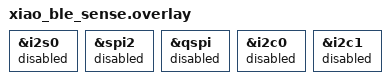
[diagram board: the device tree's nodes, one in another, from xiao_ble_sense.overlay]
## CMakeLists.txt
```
# SPDX-License-Identifier: Apache-2.0
set(BOARD xiao_ble/nrf52840/sense)
cmake_minimum_required(VERSION 3.20.0)
set(KCONFIG_ROOT ${CMAKE_CURRENT_SOURCE_DIR}/Kconfig)
find_package(Zephyr REQUIRED HINTS $ENV{ZEPHYR_BASE})
project(xiao_minimal)
enable_language(C ASM)

target_include_directories(app PRIVATE
  ${CMAKE_CURRENT_SOURCE_DIR}/../devkit/src
)

target_sources(app PRIVATE
  src/main.c
  src/transport.c
  src/stubs.c

  ../devkit/src/mic.c
  ../devkit/src/codec.c
  ../devkit/src/led.c
  ../devkit/src/button.c
  ../devkit/src/usb.c
  ../devkit/src/wdog_facade.c
  ../devkit/src/lib/battery/battery.c
)

target_sources_ifdef(CONFIG_OMI_CODEC_OPUS app PRIVATE
  ../devkit/src/lib/opus-1.2.1/A2NLSF.c
  ../devkit/src/lib/opus-1.2.1/CNG.c
  ../devkit/src/lib/opus-1.2.1/HP_variable_cutoff.c
  ../devkit/src/lib/opus-1.2.1/LPC_analysis_filter.c
  ../devkit/src/lib/opus-1.2.1/LPC_fit.c
  ../devkit/src/lib/opus-1.2.1/LPC_inv_pred_gain.c
  ../devkit/src/lib/opus-1.2.1/LP_variable_cutoff.c
  ../devkit/src/lib/opus-1.2.1/LTP_analysis_filter_FIX.c
  ../devkit/src/lib/opus-1.2.1/LTP_scale_ctrl_FIX.c
  ../devkit/src/lib/opus-1.2.1/NLSF2A.c
  ../devkit/src/lib/opus-1.2.1/NLSF_VQ.c
  ../devkit/src/lib/opus-1.2.1/NLSF_VQ_weights_laroia.c
  ../devkit/src/lib/opus-1.2.1/NLSF_decode.c
  ../devkit/src/lib/opus-1.2.1/NLSF_del_dec_quant.c
  ../devkit/src/lib/opus-1.2.1/NLSF_encode.c
  ../devkit/src/lib/opus-1.2.1/NLSF_stabilize.c
  ../devkit/src/lib/opus-1.2.1/NLSF_unpack.c
  ../devkit/src/lib/opus-1.2.1/NSQ.c
  ../devkit/src/lib/opus-1.2.1/NSQ_del_dec.c
  ../devkit/src/lib/opus-1.2.1/PLC.c
  ../devkit/src/lib/opus-1.2.1/VAD.c
  ../devkit/src/lib/opus-1.2.1/VQ_WMat_EC.c
  ../devkit/src/lib/opus-1.2.1/ana_filt_bank_1.c
  ../devkit/src/lib/opus-1.2.1/analysis.c
  ../devkit/src/lib/opus-1.2.1/apply_sine_window_FIX.c
  ../devkit/src/lib/opus-1.2.1/autocorr_FIX.c
  ../devkit/src/lib/opus-1.2.1/bands.c
  ../devkit/src/lib/opus-1.2.1/biquad_alt.c
  ../devkit/src/lib/opus-1.2.1/burg_modified_FIX.c
  ../devkit/src/lib/opus-1.2.1/bwexpander.c
  ../devkit/src/lib/opus-1.2.1/bwexpander_32.c
  ../devkit/src/lib/opus-1.2.1/celt.c
  ../devkit/src/lib/opus-1.2.1/celt_decoder.c
  ../devkit/src/lib/opus-1.2.1/celt_encoder.c
  ../devkit/src/lib/opus-1.2.1/celt_lpc.c
  ../devkit/src/lib/opus-1.2.1/arm/celt_pitch_xcorr_arm_gcc.s
  ../devkit/src/lib/opus-1.2.1/check_control_input.c
  ../devkit/src/lib/opus-1.2.1/code_signs.c
  ../devkit/src/lib/opus-1.2.1/control_SNR.c
  ../devkit/src/lib/opus-1.2.1/control_audio_bandwidth.c
  ../devkit/src/lib/opus-1.2.1/control_codec.c
  ../devkit/src/lib/opus-1.2.1/corrMatrix_FIX.c
  ../devkit/src/lib/opus-1.2.1/cwrs.c
  ../devkit/src/lib/opus-1.2.1/debug.c
  ../devkit/src/lib/opus-1.2.1/dec_API.c
  ../devkit/src/lib/opus-1.2.1/decode_core.c
  ../devkit/src/lib/opus-1.2.1/decode_frame.c
  ../devkit/src/lib/opus-1.2.1/decode_indices.c
  ../devkit/src/lib/opus-1.2.1/decode_parameters.c
  ../devkit/src/lib/opus-1.2.1/decode_pitch.c
  ../devkit/src/lib/opus-1.2.1/decode_pulses.c
  ../devkit/src/lib/opus-1.2.1/decoder_set_fs.c
  ../devkit/src/lib/opus-1.2.1/enc_API.c
  ../devkit/src/lib/opus-1.2.1/encode_frame_FIX.c
  ../devkit/src/lib/opus-1.2.1/encode_indices.c
  ../devkit/src/lib/opus-1.2.1/encode_pulses.c
  ../devkit/src/lib/opus-1.2.1/entcode.c
  ../devkit/src/lib/opus-1.2.1/entdec.c
  ../devkit/src/lib/opus-1.2.1/entenc.c
  ../devkit/src/lib/opus-1.2.1/find_LPC_FIX.c
  ../devkit/src/lib/opus-1.2.1/find_LTP_FIX.c
  ../devkit/src/lib/opus-1.2.1/find_pitch_lags_FIX.c
  ../devkit/src/lib/opus-1.2.1/find_pred_coefs_FIX.c
  ../devkit/src/lib/opus-1.2.1/gain_quant.c
  ../devkit/src/lib/opus-1.2.1/init_decoder.c
  ../devkit/src/lib/opus-1.2.1/init_encoder.c
  ../devkit/src/lib/opus-1.2.1/inner_prod_aligned.c
  ../devkit/src/lib/opus-1.2.1/interpolate.c
  ../devkit/src/lib/opus-1.2.1/k2a_FIX.c
  ../devkit/src/lib/opus-1.2.1/k2a_Q16_FIX.c
  ../devkit/src/lib/opus-1.2.1/kiss_fft.c
  ../devkit/src/lib/opus-1.2.1/laplace.c
  ../devkit/src/lib/opus-1.2.1/lin2log.c
  ../devkit/src/lib/opus-1.2.1/log2lin.c
  ../devkit/src/lib/opus-1.2.1/mathops.c
  ../devkit/src/lib/opus-1.2.1/mdct.c
  ../devkit/src/lib/opus-1.2.1/mlp.c
  ../devkit/src/lib/opus-1.2.1/mlp_data.c
  ../devkit/src/lib/opus-1.2.1/modes.c
  ../devkit/src/lib/opus-1.2.1/noise_shape_analysis_FIX.c
  ../devkit/src/lib/opus-1.2.1/opus.c
  ../devkit/src/lib/opus-1.2.1/opus_decoder.c
  ../devkit/src/lib/opus-1.2.1/opus_encoder.c
  ../devkit/src/lib/opus-1.2.1/opus_multistream.c
  ../devkit/src/lib/opus-1.2.1/opus_multistream_decoder.c
  ../devkit/src/lib/opus-1.2.1/opus_multistream_encoder.c
  ../devkit/src/lib/opus-1.2.1/pitch.c
  ../devkit/src/lib/opus-1.2.1/pitch_analysis_core_FIX.c
  ../devkit/src/lib/opus-1.2.1/pitch_est_tables.c
  ../devkit/src/lib/opus-1.2.1/process_NLSFs.c
  ../devkit/src/lib/opus-1.2.1/process_gains_FIX.c
  ../devkit/src/lib/opus-1.2.1/quant_LTP_gains.c
  ../devkit/src/lib/opus-1.2.1/quant_bands.c
  ../devkit/src/lib/opus-1.2.1/rate.c
  ../devkit/src/lib/opus-1.2.1/regularize_correlations_FIX.c
  ../devkit/src/lib/opus-1.2.1/repacketizer.c
  ../devkit/src/lib/opus-1.2.1/resampler.c
  ../devkit/src/lib/opus-1.2.1/resampler_down2.c
  ../devkit/src/lib/opus-1.2.1/resampler_down2_3.c
  ../devkit/src/lib/opus-1.2.1/resampler_private_AR2.c
  ../devkit/src/lib/opus-1.2.1/resampler_private_IIR_FIR.c
  ../devkit/src/lib/opus-1.2.1/resampler_private_down_FIR.c
  ../devkit/src/lib/opus-1.2.1/resampler_private_up2_HQ.c
  ../devkit/src/lib/opus-1.2.1/resampler_rom.c
  ../devkit/src/lib/opus-1.2.1/residual_energy16_FIX.c
  ../devkit/src/lib/opus-1.2.1/residual_energy_FIX.c
  ../devkit/src/lib/opus-1.2.1/schur64_FIX.c
  ../devkit/src/lib/opus-1.2.1/schur_FIX.c
  ../devkit/src/lib/opus-1.2.1/shell_coder.c
  ../devkit/src/lib/opus-1.2.1/sigm_Q15.c
  ../devkit/src/lib/opus-1.2.1/sort.c
  ../devkit/src/lib/opus-1.2.1/stereo_LR_to_MS.c
  ../devkit/src/lib/opus-1.2.1/stereo_MS_to_LR.c
  ../devkit/src/lib/opus-1.2.1/stereo_decode_pred.c
  ../devkit/src/lib/opus-1.2.1/stereo_encode_pred.c
  ../devkit/src/lib/opus-1.2.1/stereo_find_predictor.c
  ../devkit/src/lib/opus-1.2.1/stereo_quant_pred.c
  ../devkit/src/lib/opus-1.2.1/sum_sqr_shift.c
  ../devkit/src/lib/opus-1.2.1/table_LSF_cos.c
  ../devkit/src/lib/opus-1.2.1/tables_LTP.c
  ../devkit/src/lib/opus-1.2.1/tables_NLSF_CB_NB_MB.c
  ../devkit/src/lib/opus-1.2.1/tables_NLSF_CB_WB.c
  ../devkit/src/lib/opus-1.2.1/tables_gain.c
  ../devkit/src/lib/opus-1.2.1/tables_other.c
  ../devkit/src/lib/opus-1.2.1/tables_pitch_lag.c
  ../devkit/src/lib/opus-1.2.1/tables_pulses_per_block.c
  ../devkit/src/lib/opus-1.2.1/vector_ops_FIX.c
  ../devkit/src/lib/opus-1.2.1/vq.c
  ../devkit/src/lib/opus-1.2.1/warped_autocorrelation_FIX.c
)

set(CMAKE_C_FLAGS "${CMAKE_C_FLAGS} -DARM_MATH_CM4")
set(CMAKE_C_FLAGS "${CMAKE_C_FLAGS} -DOPUS_ARM_ASM")
set(CMAKE_C_FLAGS "${CMAKE_C_FLAGS} -DOPUS_ARM_INLINE_ASM")
set(CMAKE_C_FLAGS "${CMAKE_C_FLAGS} -DOPUS_ARM_INLINE_EDSP")
set(CMAKE_C_FLAGS "${CMAKE_C_FLAGS} -DOPUS_ARM_INLINE_MEDIA")
set(CMAKE_C_FLAGS "${CMAKE_C_FLAGS} -DOPUS_ARM_MAY_HAVE_EDSP")
set(CMAKE_C_FLAGS "${CMAKE_C_FLAGS} -DOPUS_ARM_PRESUME_EDSP")
set(CMAKE_C_FLAGS "${CMAKE_C_FLAGS} -DOPUS_BUILD")
set(CMAKE_C_FLAGS "${CMAKE_C_FLAGS} -DUSE_ALLOCA")
set(CMAKE_C_FLAGS "${CMAKE_C_FLAGS} -DFIXED_POINT -DDISABLE_FLOAT_API")
set(CMAKE_C_FLAGS "${CMAKE_C_FLAGS} -DHAVE_CONFIG_H")
set(CMAKE_C_FLAGS "${CMAKE_C_FLAGS} -DHAVE_ALLOCA_H")
set(CMAKE_C_FLAGS "${CMAKE_C_FLAGS} -fsingle-precision-constant")
set(CMAKE_C_FLAGS "${CMAKE_C_FLAGS} -DHAVE_LRINT -DHAVE_LRINTF")
```

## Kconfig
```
source "Kconfig.zephyr"

menu "Attune XIAO minimal options"

config OMI_CODEC_OPUS
    bool "Enable Opus codec"
    default y

config OMI_ENABLE_OFFLINE_STORAGE
    bool "Enable offline storage"
    select DISK_ACCESS
    select FILE_SYSTEM
    select FAT_FILESYSTEM_ELM
    select FS_FATFS_MOUNT_MKFS
    help
        Enable offline SD-card storage support.
    default n

config OMI_ENABLE_ACCELEROMETER
    bool "Enable accelerometer"
    help
        Enable accelerometer support.
    default n

config OMI_ENABLE_BUTTON
    bool "Enable button support"
    help
        Enable button handling.
    default y

config OMI_ENABLE_SPEAKER
    bool "Enable speaker support"
    help
        Enable speaker output support.
    default n

config OMI_ENABLE_BATTERY
    bool "Enable battery support"
    help
        Enable battery telemetry support.
    default y

if OMI_ENABLE_BATTERY

config OMI_BATTERY_GPIO_CHARGE_SPEED_PIN
    int "Battery charge-speed GPIO pin"
    default 13
    help
        GPIO pin index used for charger current selection.

config OMI_BATTERY_GPIO_CHARGING_ENABLE_PIN
    int "Battery charging-enable GPIO pin"
    default -1
    help
        GPIO pin index used to enable the charger path.
        Set to -1 when the board charger is autonomous (no enable pin).

config OMI_BATTERY_GPIO_CHARGE_STATUS_PIN
    int "Battery charge-status GPIO pin"
    default 17
    help
        GPIO pin index for charge status output from PMIC.
        Set to -1 when charge status is unavailable.

config OMI_BATTERY_GPIO_READ_ENABLE_PIN
    int "Battery read-enable GPIO pin"
    default 14
    help
        GPIO pin index used to enable battery voltage read circuitry.

config OMI_BATTERY_CHARGE_SPEED_ACTIVE_LOW
    bool "Charge-speed pin is active low"
    default y

config OMI_BATTERY_CHARGING_ENABLE_ACTIVE_LOW
    bool "Charging-enable pin is active low"
    default y

config OMI_BATTERY_CHARGE_STATUS_ACTIVE_LOW
    bool "Charge-status pin is active low"
    default y

config OMI_BATTERY_READ_ENABLE_ACTIVE_LOW
    bool "Read-enable pin is active low"
    default y

config OMI_BATTERY_ADC_R1_KOHM
    int "Battery divider R1 value (kOhm)"
    default 1000
    help
        Top resistor value for battery divider calibration.

config OMI_BATTERY_ADC_R2_KOHM
    int "Battery divider R2 value (kOhm)"
    default 510
    help
        Bottom resistor value for battery divider calibration.

endif

config OMI_ENABLE_USB
    bool "Enable USB support"
    help
        Enable USB power-check support.
    default y

config OMI_ENABLE_HAPTIC
    bool "Enable haptic support"
    help
        Enable haptic feedback support.
    default n

endmenu
```

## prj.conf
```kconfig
# Bare XIAO nRF52840 Sense minimal firmware

# Core HW
CONFIG_GPIO=y
CONFIG_ADC=y
CONFIG_NRFX_PDM=y
CONFIG_FLASH=y
CONFIG_WATCHDOG=y
CONFIG_WDT_DISABLE_AT_BOOT=n

# BLE
CONFIG_BT=y
CONFIG_BT_PERIPHERAL=y
CONFIG_BT_DEVICE_NAME="Attune XIAO Minimal"
CONFIG_BT_MAX_CONN=1
CONFIG_BT_MAX_PAIRED=1
CONFIG_BT_DEVICE_APPEARANCE=22
CONFIG_BT_GATT_DYNAMIC_DB=y
CONFIG_BT_BAS=y
CONFIG_BT_DIS=y
CONFIG_BT_DIS_PNP=n
CONFIG_BT_DIS_MODEL="Attune XIAO Minimal"
CONFIG_BT_DIS_MANUF="Based Hardware"
CONFIG_BT_DIS_FW_REV=y
CONFIG_BT_DIS_HW_REV=y
CONFIG_BT_DIS_FW_REV_STR="0.1.0"
CONFIG_BT_DIS_HW_REV_STR="Seeed XIAO nRF52840 Sense"

CONFIG_BT_CTLR_TX_PWR_ANTENNA=8
CONFIG_BT_PHY_UPDATE=y
CONFIG_BT_L2CAP_TX_MTU=498
CONFIG_BT_CTLR_DATA_LENGTH_MAX=251
CONFIG_BT_CTLR_PHY_2M=y
CONFIG_BT_CONN_TX_MAX=20
CONFIG_BT_BUF_ACL_RX_SIZE=1024
CONFIG_BT_L2CAP_TX_BUF_COUNT=10
CONFIG_BT_BUF_ACL_TX_SIZE=2048
CONFIG_BT_USER_DATA_LEN_UPDATE=y
CONFIG_BT_AUTO_DATA_LEN_UPDATE=y
CONFIG_BT_USER_PHY_UPDATE=y
CONFIG_BT_AUTO_PHY_UPDATE=y

# Logging / console for bring-up
CONFIG_CONSOLE=y
CONFIG_PRINTK=y
CONFIG_LOG=y
CONFIG_LOG_PRINTK=y
CONFIG_SERIAL=y
CONFIG_UART_CONSOLE=y
CONFIG_LOG_DEFAULT_LEVEL=3

# Omi feature toggles
CONFIG_OMI_CODEC_OPUS=y
CONFIG_OMI_ENABLE_OFFLINE_STORAGE=n
CONFIG_OMI_ENABLE_ACCELEROMETER=n
CONFIG_OMI_ENABLE_BUTTON=y
CONFIG_OMI_ENABLE_SPEAKER=n
CONFIG_OMI_ENABLE_BATTERY=y
CONFIG_OMI_ENABLE_USB=y
CONFIG_OMI_ENABLE_HAPTIC=n
CONFIG_OMI_BATTERY_GPIO_CHARGE_SPEED_PIN=-1
CONFIG_OMI_BATTERY_GPIO_CHARGING_ENABLE_PIN=-1
CONFIG_OMI_BATTERY_GPIO_CHARGE_STATUS_PIN=-1
CONFIG_OMI_BATTERY_GPIO_READ_ENABLE_PIN=-1
CONFIG_OMI_BATTERY_CHARGE_SPEED_ACTIVE_LOW=y
CONFIG_OMI_BATTERY_READ_ENABLE_ACTIVE_LOW=y
CONFIG_OMI_BATTERY_CHARGE_STATUS_ACTIVE_LOW=y
CONFIG_OMI_BATTERY_ADC_R1_KOHM=1000
CONFIG_OMI_BATTERY_ADC_R2_KOHM=510

CONFIG_RING_BUFFER=y
CONFIG_HEAP_MEM_POOL_SIZE=512
CONFIG_MAIN_STACK_SIZE=3072
```

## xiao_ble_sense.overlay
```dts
/* Bare XIAO Sense minimal overlay: explicitly disable peripherals not present */

&i2s0 {
    status = "disabled";
};

&spi2 {
    status = "disabled";
};

&qspi {
    status = "disabled";
};

&i2c0 {
    status = "disabled";
};

&i2c1 {
    status = "disabled";
};
```

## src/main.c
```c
#include <errno.h>
#include <zephyr/kernel.h>
#include <zephyr/logging/log.h>
#include <hal/nrf_power.h>

#include "button.h"
#include "codec.h"
#include "config.h"
#include "led.h"
#include "lib/battery/battery.h"
#include "mic.h"
#include "transport.h"
#include "usb.h"
#include "wdog_facade.h"

LOG_MODULE_REGISTER(main, CONFIG_LOG_DEFAULT_LEVEL);

bool is_connected = false;
bool is_charging = false;
extern bool is_off;
extern bool usb_charge;
static bool charger_state_initialized = false;
static bool charger_enabled = false;
static int64_t last_codec_error_log_ms = 0;
static int64_t last_battery_diag_log_ms = 0;

static void codec_handler(uint8_t *data, size_t len)
{
    if (!is_connected) {
        return;
    }

    int err = broadcast_audio_packets(data, len);
    if (err) {
        const int64_t now_ms = k_uptime_get();
        if ((now_ms - last_codec_error_log_ms) >= 1000) {
            last_codec_error_log_ms = now_ms;
            LOG_WRN("Audio packet broadcast backpressure (err=%d)", err);
        }
    }
}

static void mic_handler(int16_t *buffer)
{
    if (!is_connected) {
        return;
    }

    int err = codec_receive_pcm(buffer, MIC_BUFFER_SAMPLES);
    if (err) {
        const int64_t now_ms = k_uptime_get();
        if ((now_ms - last_codec_error_log_ms) >= 1000) {
            last_codec_error_log_ms = now_ms;
            LOG_WRN("PCM ingest backpressure (err=%d)", err);
        }
    }
}

void set_led_state(void)
{
    if (usb_charge) {
        is_charging = !is_charging;
        set_led_green(is_charging);
    } else {
        set_led_green(false);
    }

    if (is_off) {
        set_led_red(false);
        set_led_blue(false);
        return;
    }

    if (is_connected) {
        set_led_blue(true);
        set_led_red(false);
    } else {
        set_led_blue(false);
        set_led_red(true);
    }
}

static void apply_charger_policy(void)
{
#ifdef CONFIG_OMI_ENABLE_BATTERY
#if defined(CONFIG_OMI_BATTERY_GPIO_CHARGING_ENABLE_PIN) && (CONFIG_OMI_BATTERY_GPIO_CHARGING_ENABLE_PIN < 0)
    // XIAO build: charger enable is not firmware-controlled.
    return;
#else
    const bool should_charge = usb_charge;
    if (charger_state_initialized && charger_enabled == should_charge) {
        return;
    }

    const int err = should_charge ? battery_charge_start() : battery_charge_stop();
    if (err) {
        LOG_WRN("Battery charge policy update failed (usb=%d, err=%d)", should_charge, err);
        return;
    }

    charger_state_initialized = true;
    charger_enabled = should_charge;
    LOG_INF("Battery charger %s (usb=%d)", should_charge ? "enabled" : "disabled", usb_charge);
#endif
#endif
}

static void log_battery_diagnostics(void)
{
#ifdef CONFIG_OMI_ENABLE_BATTERY
    const int64_t now_ms = k_uptime_get();
    if ((now_ms - last_battery_diag_log_ms) < 10000) {
        return;
    }
    last_battery_diag_log_ms = now_ms;

    uint16_t battery_millivolt = 0;
    uint8_t battery_percent = 0xFF;
    bool charging = false;
    const int mv_err = battery_get_millivolt(&battery_millivolt);
    const int pct_err = (mv_err == 0)
        ? battery_get_percentage(&battery_percent, battery_millivolt)
        : -ENOTSUP;
    const int charge_err = battery_is_charge_enabled(&charging);

    LOG_INF("Battery main diag: mv=%u pct=%u usb=%d charging=%d errs[mv=%d pct=%d chg=%d]",
            battery_millivolt,
            battery_percent,
            usb_charge ? 1 : 0,
            charging ? 1 : 0,
            mv_err,
            pct_err,
            charge_err);
#endif
}

int main(void)
{
    int err;

    LOG_INF("Booting minimal XIAO firmware");
    LOG_INF("Model: %s", CONFIG_BT_DIS_MODEL);
    LOG_INF("FW: %s", CONFIG_BT_DIS_FW_REV_STR);
    const uint32_t reset_reason = NRF_POWER->RESETREAS;
    NRF_POWER->RESETREAS = reset_reason;
    LOG_INF("Reset reason: 0x%08x", reset_reason);

    err = led_start();
    if (err) {
        LOG_ERR("LED init failed: %d", err);
        return err;
    }

    err = watchdog_init();
    if (err) {
        LOG_WRN("Watchdog init failed: %d", err);
    }

#ifdef CONFIG_OMI_ENABLE_BATTERY
    err = battery_init();
    if (err) {
        LOG_ERR("Battery init failed: %d", err);
        return err;
    }
#endif

#ifdef CONFIG_OMI_ENABLE_BUTTON
    err = button_init();
    if (err) {
        LOG_ERR("Button init failed: %d", err);
        return err;
    }
    activate_button_work();
#endif

#ifdef CONFIG_OMI_ENABLE_USB
    err = init_usb();
    if (err) {
        LOG_ERR("USB init failed: %d", err);
        return err;
    }
#endif

#ifdef CONFIG_OMI_ENABLE_BATTERY
    apply_charger_policy();
#endif

    err = transport_start();
    if (err) {
        LOG_ERR("Transport start failed: %d", err);
        return err;
    }

    set_codec_callback(codec_handler);
    err = codec_start();
    if (err) {
        LOG_ERR("Codec start failed: %d", err);
        return err;
    }

    set_mic_callback(mic_handler);
    err = mic_start();
    if (err) {
        LOG_ERR("Mic start failed: %d", err);
        return err;
    }
    // Keep capture path off until BLE client connects or explicitly resumes.
    mic_off();

    LOG_INF("Minimal firmware initialized");

    while (1) {
        watchdog_feed();
        apply_charger_policy();
        log_battery_diagnostics();
        set_led_state();
        k_msleep(500);
    }

    return 0;
}
```

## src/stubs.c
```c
#include <stdbool.h>
#include <stdint.h>
#include <zephyr/kernel.h>

#include "speaker.h"

int speaker_init(void) { return 0; }
uint16_t speak(uint16_t len, const void *buf)
{
    ARG_UNUSED(buf);
    return len;
}
int play_boot_sound(void) { return 0; }
int init_haptic_pin(void) { return 0; }
void play_haptic_milli(uint32_t duration) { ARG_UNUSED(duration); }
void speaker_off(void) {}
void register_speaker_service(void) {}

int mount_sd_card(void) { return 0; }
void sd_on(void) {}
void sd_off(void) {}
bool is_sd_on(void) { return false; }
int write_to_file(uint8_t *buf, uint32_t len)
{
    ARG_UNUSED(buf);
    ARG_UNUSED(len);
    return 0;
}
uint32_t get_file_size(uint8_t file_num)
{
    ARG_UNUSED(file_num);
    return 0;
}
int get_offset(void) { return 0; }

int storage_init(void) { return 0; }

bool storage_is_on = false;
uint8_t file_count = 0;
uint32_t file_num_array[2] = {0};
```

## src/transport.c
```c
#include "transport.h"

#include <errno.h>
#include <zephyr/bluetooth/bluetooth.h>
#include <zephyr/bluetooth/gatt.h>
#include <zephyr/bluetooth/services/bas.h>
#include <zephyr/kernel.h>
#include <zephyr/logging/log.h>
#include <zephyr/sys/ring_buffer.h>
#include <zephyr/sys/util.h>

#include "button.h"
#include "codec.h"
#include "config.h"
#include "lib/battery/battery.h"
#include "mic.h"
#include "usb.h"
#include "utils.h"

LOG_MODULE_REGISTER(transport, CONFIG_LOG_DEFAULT_LEVEL);

extern bool is_connected;
extern bool is_off;
extern bool usb_charge;

struct bt_conn *current_connection = NULL;
uint16_t current_mtu = 0;
static struct ring_buf ring_buf;
static volatile bool stream_paused = true;
static volatile bool stream_notify_enabled = false;

static void audio_ccc_config_changed_handler(const struct bt_gatt_attr *attr, uint16_t value)
{
    ARG_UNUSED(attr);
    stream_notify_enabled = (value == BT_GATT_CCC_NOTIFY);
    if (!stream_notify_enabled) {
        ring_buf_reset(&ring_buf);
        mic_off();
    } else if (!stream_paused && is_connected) {
        mic_on();
    }
}

static ssize_t audio_data_read_characteristic(struct bt_conn *conn,
                                              const struct bt_gatt_attr *attr,
                                              void *buf,
                                              uint16_t len,
                                              uint16_t offset)
{
    return bt_gatt_attr_read(conn, attr, buf, len, offset, NULL, 0);
}

static ssize_t audio_codec_read_characteristic(struct bt_conn *conn,
                                               const struct bt_gatt_attr *attr,
                                               void *buf,
                                               uint16_t len,
                                               uint16_t offset)
{
    uint8_t value[1] = {CODEC_ID};
    return bt_gatt_attr_read(conn, attr, buf, len, offset, value, sizeof(value));
}

static ssize_t audio_mic_gain_read_characteristic(struct bt_conn *conn,
                                                  const struct bt_gatt_attr *attr,
                                                  void *buf,
                                                  uint16_t len,
                                                  uint16_t offset)
{
    ARG_UNUSED(attr);
    const uint8_t level = mic_get_gain_level();
    return bt_gatt_attr_read(conn, attr, buf, len, offset, &level, sizeof(level));
}

static ssize_t audio_mic_gain_write_characteristic(struct bt_conn *conn,
                                                   const struct bt_gatt_attr *attr,
                                                   const void *buf,
                                                   uint16_t len,
                                                   uint16_t offset,
                                                   uint8_t flags)
{
    ARG_UNUSED(conn);
    ARG_UNUSED(attr);
    ARG_UNUSED(offset);
    ARG_UNUSED(flags);

    if (buf == NULL || len < 1) {
        return 0;
    }

    const uint8_t requested = ((const uint8_t *)buf)[0];
    mic_set_gain_level(requested);
    return len;
}

enum {
    AUDIO_CTRL_CMD_PAUSE_STREAM = 0x01,
    AUDIO_CTRL_CMD_RESUME_STREAM = 0x02,
    AUDIO_CTRL_CMD_ENTER_DEEP_SLEEP = 0x03,
    AUDIO_CTRL_CMD_NOTIFY_STATUS = 0x04,
};

enum {
    AUDIO_STATUS_FLAG_USB_POWER = 1 << 0,
    AUDIO_STATUS_FLAG_CHARGING_ENABLED = 1 << 1,
    AUDIO_STATUS_FLAG_STREAM_PAUSED = 1 << 2,
};

static bool battery_filter_initialized = false;
static uint16_t battery_filtered_mv = 0;
static uint8_t battery_filtered_percent = 0xFF;
static int64_t battery_last_update_ms = 0;
static int64_t battery_diag_last_log_ms = 0;

static uint8_t stabilize_battery_percent(uint8_t raw_percent, uint16_t raw_mv)
{
    if (raw_percent == 0xFF) {
        return battery_filter_initialized ? battery_filtered_percent : raw_percent;
    }

    const int64_t now_ms = k_uptime_get();
    if (!battery_filter_initialized) {
        battery_filter_initialized = true;
        battery_filtered_mv = raw_mv;
        battery_filtered_percent = raw_percent;
        battery_last_update_ms = now_ms;
        return battery_filtered_percent;
    }

    if (raw_mv > 0) {
        // Exponential moving average to reduce load-induced voltage swings.
        battery_filtered_mv = (uint16_t)(((uint32_t)battery_filtered_mv * 7U + raw_mv) / 8U);
    }

    uint8_t candidate = raw_percent;
    if (battery_filtered_mv > 0) {
        (void)battery_get_percentage(&candidate, battery_filtered_mv);
    }

    int elapsed_s = (int)((now_ms - battery_last_update_ms) / 1000);
    if (elapsed_s < 1) {
        elapsed_s = 1;
    }

    const int prev = (int)battery_filtered_percent;
    const int max_rise = MIN(24, 2 + elapsed_s);
    const int max_fall = MIN(28, 3 + (elapsed_s * 2));
    int delta = (int)candidate - prev;
    if (delta > max_rise) {
        candidate = (uint8_t)(prev + max_rise);
    } else if (-delta > max_fall) {
        candidate = (uint8_t)(prev - max_fall);
    }

    battery_filtered_percent = candidate;
    battery_last_update_ms = now_ms;
    return battery_filtered_percent;
}

static ssize_t audio_control_write_characteristic(struct bt_conn *conn,
                                                  const struct bt_gatt_attr *attr,
                                                  const void *buf,
                                                  uint16_t len,
                                                  uint16_t offset,
                                                  uint8_t flags);
static ssize_t audio_status_read_characteristic(struct bt_conn *conn,
                                                const struct bt_gatt_attr *attr,
                                                void *buf,
                                                uint16_t len,
                                                uint16_t offset);
static void audio_status_ccc_config_changed_handler(const struct bt_gatt_attr *attr, uint16_t value);
static void audio_notify_status(struct bt_conn *conn);
static void audio_build_status_payload(uint8_t payload[5]);

static struct bt_uuid_128 audio_service_uuid =
    BT_UUID_INIT_128(BT_UUID_128_ENCODE(0x19B10000, 0xE8F2, 0x537E, 0x4F6C, 0xD104768A1214));
static struct bt_uuid_128 audio_characteristic_data_uuid =
    BT_UUID_INIT_128(BT_UUID_128_ENCODE(0x19B10001, 0xE8F2, 0x537E, 0x4F6C, 0xD104768A1214));
static struct bt_uuid_128 audio_characteristic_format_uuid =
    BT_UUID_INIT_128(BT_UUID_128_ENCODE(0x19B10002, 0xE8F2, 0x537E, 0x4F6C, 0xD104768A1214));
static struct bt_uuid_128 audio_characteristic_mic_gain_uuid =
    BT_UUID_INIT_128(BT_UUID_128_ENCODE(0x19B10003, 0xE8F2, 0x537E, 0x4F6C, 0xD104768A1214));
static struct bt_uuid_128 audio_characteristic_control_uuid =
    BT_UUID_INIT_128(BT_UUID_128_ENCODE(0x19B10004, 0xE8F2, 0x537E, 0x4F6C, 0xD104768A1214));
static struct bt_uuid_128 audio_characteristic_status_uuid =
    BT_UUID_INIT_128(BT_UUID_128_ENCODE(0x19B10005, 0xE8F2, 0x537E, 0x4F6C, 0xD104768A1214));

static struct bt_gatt_attr audio_service_attr[] = {
    BT_GATT_PRIMARY_SERVICE(&audio_service_uuid),
    BT_GATT_CHARACTERISTIC(&audio_characteristic_data_uuid.uuid,
                           BT_GATT_CHRC_READ | BT_GATT_CHRC_NOTIFY,
                           BT_GATT_PERM_READ,
                           audio_data_read_characteristic,
                           NULL,
                           NULL),
    BT_GATT_CCC(audio_ccc_config_changed_handler, BT_GATT_PERM_READ | BT_GATT_PERM_WRITE),
    BT_GATT_CHARACTERISTIC(&audio_characteristic_format_uuid.uuid,
                           BT_GATT_CHRC_READ,
                           BT_GATT_PERM_READ,
                           audio_codec_read_characteristic,
                           NULL,
                           NULL),
    BT_GATT_CHARACTERISTIC(&audio_characteristic_mic_gain_uuid.uuid,
                           BT_GATT_CHRC_READ | BT_GATT_CHRC_WRITE | BT_GATT_CHRC_WRITE_WITHOUT_RESP,
                           BT_GATT_PERM_READ | BT_GATT_PERM_WRITE,
                           audio_mic_gain_read_characteristic,
                           audio_mic_gain_write_characteristic,
                           NULL),
    BT_GATT_CHARACTERISTIC(&audio_characteristic_control_uuid.uuid,
                           BT_GATT_CHRC_WRITE | BT_GATT_CHRC_WRITE_WITHOUT_RESP,
                           BT_GATT_PERM_WRITE,
                           NULL,
                           audio_control_write_characteristic,
                           NULL),
    BT_GATT_CHARACTERISTIC(&audio_characteristic_status_uuid.uuid,
                           BT_GATT_CHRC_READ | BT_GATT_CHRC_NOTIFY,
                           BT_GATT_PERM_READ,
                           audio_status_read_characteristic,
                           NULL,
                           NULL),
    BT_GATT_CCC(audio_status_ccc_config_changed_handler, BT_GATT_PERM_READ | BT_GATT_PERM_WRITE),
};

static struct bt_gatt_service audio_service = BT_GATT_SERVICE(audio_service_attr);

static struct bt_uuid_128 dfu_service_uuid =
    BT_UUID_INIT_128(BT_UUID_128_ENCODE(0x00001530, 0x1212, 0xEFDE, 0x1523, 0x785FEABCD123));
static struct bt_uuid_128 dfu_control_point_uuid =
    BT_UUID_INIT_128(BT_UUID_128_ENCODE(0x00001531, 0x1212, 0xEFDE, 0x1523, 0x785FEABCD123));

static void dfu_ccc_config_changed_handler(const struct bt_gatt_attr *attr, uint16_t value)
{
    ARG_UNUSED(attr);
    ARG_UNUSED(value);
}

static ssize_t dfu_control_point_write_handler(struct bt_conn *conn,
                                               const struct bt_gatt_attr *attr,
                                               const void *buf,
                                               uint16_t len,
                                               uint16_t offset,
                                               uint8_t flags)
{
    ARG_UNUSED(attr);
    ARG_UNUSED(offset);
    ARG_UNUSED(flags);

    if (len == 1 && ((uint8_t *)buf)[0] == 0x06) {
        NRF_POWER->GPREGRET = 0xA8;
        NVIC_SystemReset();
    } else if (len == 2 && ((uint8_t *)buf)[0] == 0x01) {
        uint8_t notification_value = 0x10;
        bt_gatt_notify(conn, &audio_service.attrs[1], &notification_value, sizeof(notification_value));
        NRF_POWER->GPREGRET = 0xA8;
        NVIC_SystemReset();
    }
    return len;
}

static struct bt_gatt_attr dfu_service_attr[] = {
    BT_GATT_PRIMARY_SERVICE(&dfu_service_uuid),
    BT_GATT_CHARACTERISTIC(&dfu_control_point_uuid.uuid,
                           BT_GATT_CHRC_WRITE | BT_GATT_CHRC_NOTIFY,
                           BT_GATT_PERM_WRITE,
                           NULL,
                           dfu_control_point_write_handler,
                           NULL),
    BT_GATT_CCC(dfu_ccc_config_changed_handler, BT_GATT_PERM_READ | BT_GATT_PERM_WRITE),
};

static struct bt_gatt_service dfu_service = BT_GATT_SERVICE(dfu_service_attr);

static const struct bt_data bt_ad[] = {
    BT_DATA_BYTES(BT_DATA_FLAGS, (BT_LE_AD_GENERAL | BT_LE_AD_NO_BREDR)),
    BT_DATA(BT_DATA_UUID128_ALL, audio_service_uuid.val, sizeof(audio_service_uuid.val)),
    BT_DATA(BT_DATA_NAME_COMPLETE, CONFIG_BT_DEVICE_NAME, sizeof(CONFIG_BT_DEVICE_NAME) - 1),
};

static const struct bt_data bt_sd[] = {
    BT_DATA_BYTES(BT_DATA_UUID16_ALL, BT_UUID_16_ENCODE(BT_UUID_DIS_VAL)),
    BT_DATA(BT_DATA_UUID128_ALL, dfu_service_uuid.val, sizeof(dfu_service_uuid.val)),
};

static void _transport_connected(struct bt_conn *conn, uint8_t err)
{
    struct bt_conn_info info = {0};
    if (err) {
        return;
    }

    if (bt_conn_get_info(conn, &info)) {
        return;
    }

    if (current_connection != NULL) {
        bt_conn_unref(current_connection);
    }
    current_connection = bt_conn_ref(conn);
    current_mtu = info.le.data_len->tx_max_len;
    if (!stream_paused && stream_notify_enabled) {
        mic_on();
    } else {
        mic_off();
    }
    is_connected = true;
    audio_notify_status(conn);
}

static void _transport_disconnected(struct bt_conn *conn, uint8_t reason)
{
    ARG_UNUSED(conn);
    ARG_UNUSED(reason);
    is_connected = false;
    stream_paused = true;
    stream_notify_enabled = false;
    ring_buf_reset(&ring_buf);
    mic_off();

    if (current_connection != NULL) {
        bt_conn_unref(current_connection);
        current_connection = NULL;
    }
    current_mtu = 0;
}

static void _le_data_length_updated(struct bt_conn *conn, struct bt_conn_le_data_len_info *info)
{
    ARG_UNUSED(conn);
    current_mtu = info->tx_max_len;
}

static struct bt_conn_cb _callback_references = {
    .connected = _transport_connected,
    .disconnected = _transport_disconnected,
    .le_data_len_updated = _le_data_length_updated,
};

#define NET_BUFFER_HEADER_SIZE 3
#define RING_BUFFER_HEADER_SIZE 2
static uint8_t tx_queue[NETWORK_RING_BUF_SIZE * (CODEC_OUTPUT_MAX_BYTES + RING_BUFFER_HEADER_SIZE)];
static uint8_t tx_buffer[CODEC_OUTPUT_MAX_BYTES + RING_BUFFER_HEADER_SIZE];
static uint8_t tx_buffer_2[CODEC_OUTPUT_MAX_BYTES + RING_BUFFER_HEADER_SIZE];
static uint8_t pusher_temp_data[CODEC_OUTPUT_MAX_BYTES + NET_BUFFER_HEADER_SIZE];
static uint32_t tx_buffer_size = 0;
static uint16_t packet_next_index = 0;

static bool write_to_tx_queue(uint8_t *data, size_t size)
{
    if (size > CODEC_OUTPUT_MAX_BYTES) {
        return false;
    }

    tx_buffer_2[0] = size & 0xFF;
    tx_buffer_2[1] = (size >> 8) & 0xFF;
    memcpy(tx_buffer_2 + RING_BUFFER_HEADER_SIZE, data, size);

    int written = ring_buf_put(&ring_buf, tx_buffer_2, CODEC_OUTPUT_MAX_BYTES + RING_BUFFER_HEADER_SIZE);
    return written == (CODEC_OUTPUT_MAX_BYTES + RING_BUFFER_HEADER_SIZE);
}

static bool read_from_tx_queue(void)
{
    tx_buffer_size = ring_buf_get(&ring_buf, tx_buffer, CODEC_OUTPUT_MAX_BYTES + RING_BUFFER_HEADER_SIZE);
    if (tx_buffer_size != (CODEC_OUTPUT_MAX_BYTES + RING_BUFFER_HEADER_SIZE)) {
        return false;
    }
    tx_buffer_size = tx_buffer[0] + (tx_buffer[1] << 8);
    return true;
}

static void audio_status_ccc_config_changed_handler(const struct bt_gatt_attr *attr, uint16_t value)
{
    ARG_UNUSED(attr);
    ARG_UNUSED(value);
}

static void audio_build_status_payload(uint8_t payload[5])
{
    uint16_t battery_millivolt = 0;
    uint8_t battery_percent = 0xFF;
    uint8_t battery_percent_raw = 0xFF;
    bool charge_enabled = false;
    int battery_mv_err = -ENOTSUP;
    int battery_percent_err = -ENOTSUP;
    int battery_charge_err = -ENOTSUP;
    uint8_t flags = 0;

    if (usb_charge) {
        flags |= AUDIO_STATUS_FLAG_USB_POWER;
    }
    if (stream_paused) {
        flags |= AUDIO_STATUS_FLAG_STREAM_PAUSED;
    }

#ifdef CONFIG_OMI_ENABLE_BATTERY
    battery_mv_err = battery_get_millivolt(&battery_millivolt);
    if (battery_mv_err == 0) {
        battery_percent_err = battery_get_percentage(&battery_percent_raw, battery_millivolt);
        if (battery_percent_err == 0) {
            battery_percent = stabilize_battery_percent(battery_percent_raw, battery_millivolt);
        } else {
            battery_percent = battery_percent_raw;
        }
    }
    battery_charge_err = battery_is_charge_enabled(&charge_enabled);
    if (battery_charge_err == 0 && charge_enabled) {
        flags |= AUDIO_STATUS_FLAG_CHARGING_ENABLED;
    }
#else
    ARG_UNUSED(charge_enabled);
#endif

    payload[0] = 1; // payload version
    payload[1] = flags;
    payload[2] = battery_percent;
    payload[3] = (uint8_t)(battery_millivolt & 0xFF);
    payload[4] = (uint8_t)((battery_millivolt >> 8) & 0xFF);

    const int64_t now_ms = k_uptime_get();
    if ((now_ms - battery_diag_last_log_ms) >= 10000) {
        battery_diag_last_log_ms = now_ms;
        LOG_INF(
            "Battery diag: mv=%u raw_pct=%u pct=%u usb=%d charging=%d paused=%d errs[mv=%d pct=%d chg=%d]",
            battery_millivolt,
            battery_percent_raw,
            battery_percent,
            usb_charge ? 1 : 0,
            charge_enabled ? 1 : 0,
            stream_paused ? 1 : 0,
            battery_mv_err,
            battery_percent_err,
            battery_charge_err);
    }
}

static void audio_notify_status(struct bt_conn *conn)
{
    uint8_t payload[5] = {0};
    audio_build_status_payload(payload);

    int err = bt_gatt_notify_uuid(conn, &audio_characteristic_status_uuid.uuid, audio_service.attrs, payload, sizeof(payload));
    if (err && err != -ENOTCONN) {
        LOG_DBG("Audio status notify failed: %d", err);
    }
}

static ssize_t audio_status_read_characteristic(struct bt_conn *conn,
                                                const struct bt_gatt_attr *attr,
                                                void *buf,
                                                uint16_t len,
                                                uint16_t offset)
{
    uint8_t payload[5] = {0};
    audio_build_status_payload(payload);
    return bt_gatt_attr_read(conn, attr, buf, len, offset, payload, sizeof(payload));
}

static ssize_t audio_control_write_characteristic(struct bt_conn *conn,
                                                  const struct bt_gatt_attr *attr,
                                                  const void *buf,
                                                  uint16_t len,
                                                  uint16_t offset,
                                                  uint8_t flags)
{
    ARG_UNUSED(attr);
    ARG_UNUSED(offset);
    ARG_UNUSED(flags);

    if (buf == NULL || len < 1) {
        return 0;
    }

    const uint8_t cmd = ((const uint8_t *)buf)[0];
    switch (cmd) {
    case AUDIO_CTRL_CMD_PAUSE_STREAM:
        stream_paused = true;
        ring_buf_reset(&ring_buf);
        mic_off();
        LOG_INF("Audio stream paused");
        audio_notify_status(conn);
        break;
    case AUDIO_CTRL_CMD_RESUME_STREAM:
        stream_paused = false;
        if (stream_notify_enabled && is_connected) {
            mic_on();
        }
        LOG_INF("Audio stream resumed");
        audio_notify_status(conn);
        break;
    case AUDIO_CTRL_CMD_ENTER_DEEP_SLEEP:
        LOG_INF("Deep sleep command received");
        stream_paused = true;
        audio_notify_status(conn);
        is_off = true;
        bt_off();
        turnoff_all();
        break;
    case AUDIO_CTRL_CMD_NOTIFY_STATUS:
        audio_notify_status(conn);
        break;
    default:
        LOG_WRN("Unknown audio control command: 0x%02X", cmd);
        break;
    }

    return len;
}

K_THREAD_STACK_DEFINE(pusher_stack, 2048);
static struct k_thread pusher_thread;

void pusher(void)
{
    while (1) {
        struct bt_conn *conn = current_connection;
        if (conn) {
            conn = bt_conn_ref(conn);
        }

        if (conn && current_mtu >= MINIMAL_PACKET_SIZE &&
            bt_gatt_is_subscribed(conn, &audio_service.attrs[1], BT_GATT_CCC_NOTIFY)) {

            if (stream_paused) {
                k_sleep(K_MSEC(5));
            } else if (read_from_tx_queue()) {
                uint8_t *buffer = tx_buffer + RING_BUFFER_HEADER_SIZE;
                uint32_t offset = 0;
                uint8_t index = 0;

                while (offset < tx_buffer_size) {
                    uint32_t id = packet_next_index++;
                    uint32_t packet_size = MIN(current_mtu - NET_BUFFER_HEADER_SIZE, tx_buffer_size - offset);
                    pusher_temp_data[0] = id & 0xFF;
                    pusher_temp_data[1] = (id >> 8) & 0xFF;
                    pusher_temp_data[2] = index;
                    memcpy(pusher_temp_data + NET_BUFFER_HEADER_SIZE, buffer + offset, packet_size);

                    offset += packet_size;
                    index++;

                    (void)bt_gatt_notify(conn,
                                         &audio_service.attrs[1],
                                         pusher_temp_data,
                                         packet_size + NET_BUFFER_HEADER_SIZE);
                }
            }
        }

        if (conn) {
            bt_conn_unref(conn);
        }

        k_yield();
    }
}

int transport_start(void)
{
    bt_conn_cb_register(&_callback_references);

    int err = bt_enable(NULL);
    if (err) {
        LOG_ERR("BLE init failed: %d", err);
        return err;
    }

#ifdef CONFIG_OMI_ENABLE_BUTTON
    register_button_service();
#endif

    bt_gatt_service_register(&audio_service);
    bt_gatt_service_register(&dfu_service);

    err = bt_le_adv_start(BT_LE_ADV_CONN, bt_ad, ARRAY_SIZE(bt_ad), bt_sd, ARRAY_SIZE(bt_sd));
    if (err) {
        LOG_ERR("Adv start failed: %d", err);
        return err;
    }

    ring_buf_init(&ring_buf, sizeof(tx_queue), tx_queue);
    k_thread_create(&pusher_thread,
                    pusher_stack,
                    K_THREAD_STACK_SIZEOF(pusher_stack),
                    (k_thread_entry_t)pusher,
                    NULL,
                    NULL,
                    NULL,
                    K_PRIO_PREEMPT(7),
                    0,
                    K_NO_WAIT);

    return 0;
}

int broadcast_audio_packets(uint8_t *buffer, size_t size)
{
    if (stream_paused || !is_connected) {
        return 0;
    }

    bool subscribed = false;
    struct bt_conn *conn = current_connection;
    if (conn) {
        conn = bt_conn_ref(conn);
    }
    if (conn && current_mtu >= MINIMAL_PACKET_SIZE) {
        subscribed = bt_gatt_is_subscribed(conn, &audio_service.attrs[1], BT_GATT_CCC_NOTIFY);
    }
    if (conn) {
        bt_conn_unref(conn);
    }
    if (!subscribed) {
        stream_notify_enabled = false;
        ring_buf_reset(&ring_buf);
        return 0;
    }

    int retry_count = 0;
    while (retry_count < 3 && !write_to_tx_queue(buffer, size)) {
        k_sleep(K_MSEC(1));
        retry_count++;
    }
    return (retry_count >= 3) ? -1 : 0;
}

struct bt_conn *get_current_connection(void)
{
    return current_connection;
}

int bt_off(void)
{
    if (current_connection != NULL) {
        bt_conn_disconnect(current_connection, BT_HCI_ERR_REMOTE_USER_TERM_CONN);
        bt_conn_unref(current_connection);
        current_connection = NULL;
    }

    (void)bt_le_adv_stop();
    (void)bt_disable();
    stream_paused = true;
    stream_notify_enabled = false;
    ring_buf_reset(&ring_buf);
    mic_off();
    is_connected = false;
    current_mtu = 0;
    return 0;
}

int bt_on(void)
{
    int err = bt_enable(NULL);
    if (err) {
        return err;
    }

    stream_paused = true;
    stream_notify_enabled = false;
    mic_off();
    return bt_le_adv_start(BT_LE_ADV_CONN, bt_ad, ARRAY_SIZE(bt_ad), bt_sd, ARRAY_SIZE(bt_sd));
}

void accel_off(void)
{
    /* not used in minimal build */
}
```
